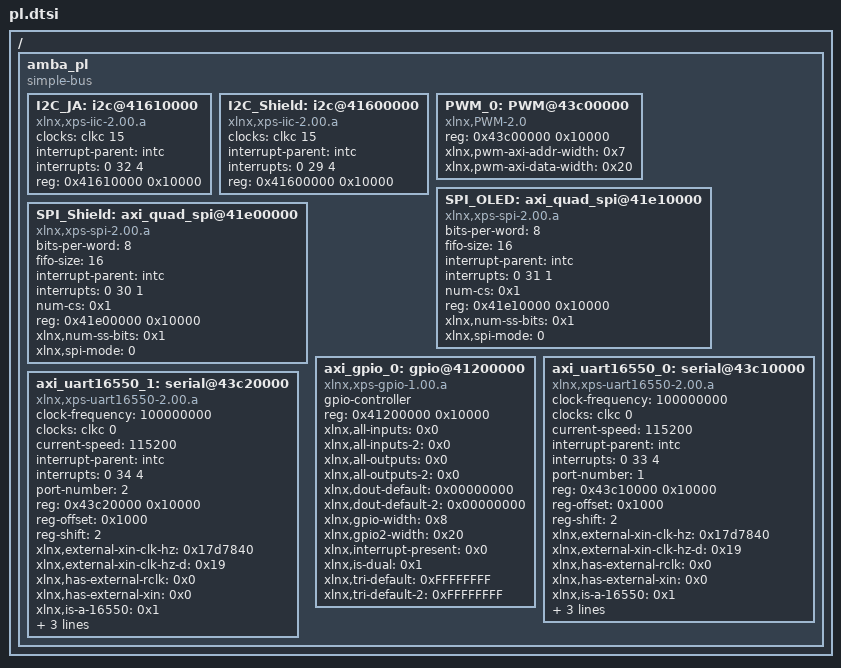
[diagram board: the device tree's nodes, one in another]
/*
 * CAUTION: This file is automatically generated by Xilinx.
 * Version:  
 * Today is: Thu Aug 31 12:42:08 2017
*/


/ {
	amba_pl: amba_pl {
		#address-cells = <1>;
		#size-cells = <1>;
		compatible = "simple-bus";
		ranges ;
		I2C_JA: i2c@41610000 {
			#address-cells = <1>;
			#size-cells = <0>;
			clock-names = "ref_clk";
			clocks = <&clkc 15>;
			compatible = "xlnx,xps-iic-2.00.a";
			interrupt-parent = <&intc>;
			interrupts = <0 32 4>;
			reg = <0x41610000 0x10000>;
		};
		I2C_Shield: i2c@41600000 {
			#address-cells = <1>;
			#size-cells = <0>;
			clock-names = "ref_clk";
			clocks = <&clkc 15>;
			compatible = "xlnx,xps-iic-2.00.a";
			interrupt-parent = <&intc>;
			interrupts = <0 29 4>;
			reg = <0x41600000 0x10000>;
		};
		PWM_0: PWM@43c00000 {
			compatible = "xlnx,PWM-2.0";
			reg = <0x43c00000 0x10000>;
			xlnx,pwm-axi-addr-width = <0x7>;
			xlnx,pwm-axi-data-width = <0x20>;
		};
		SPI_OLED: axi_quad_spi@41e10000 {
			bits-per-word = <8>;
			compatible = "xlnx,xps-spi-2.00.a";
			fifo-size = <16>;
			interrupt-parent = <&intc>;
			interrupts = <0 31 1>;
			num-cs = <0x1>;
			reg = <0x41e10000 0x10000>;
			xlnx,num-ss-bits = <0x1>;
			xlnx,spi-mode = <0>;
		};
		SPI_Shield: axi_quad_spi@41e00000 {
			bits-per-word = <8>;
			compatible = "xlnx,xps-spi-2.00.a";
			fifo-size = <16>;
			interrupt-parent = <&intc>;
			interrupts = <0 30 1>;
			num-cs = <0x1>;
			reg = <0x41e00000 0x10000>;
			xlnx,num-ss-bits = <0x1>;
			xlnx,spi-mode = <0>;
		};
		axi_gpio_0: gpio@41200000 {
			#gpio-cells = <2>;
			compatible = "xlnx,xps-gpio-1.00.a";
			gpio-controller ;
			reg = <0x41200000 0x10000>;
			xlnx,all-inputs = <0x0>;
			xlnx,all-inputs-2 = <0x0>;
			xlnx,all-outputs = <0x0>;
			xlnx,all-outputs-2 = <0x0>;
			xlnx,dout-default = <0x00000000>;
			xlnx,dout-default-2 = <0x00000000>;
			xlnx,gpio-width = <0x8>;
			xlnx,gpio2-width = <0x20>;
			xlnx,interrupt-present = <0x0>;
			xlnx,is-dual = <0x1>;
			xlnx,tri-default = <0xFFFFFFFF>;
			xlnx,tri-default-2 = <0xFFFFFFFF>;
		};
		axi_uart16550_0: serial@43c10000 {
			clock-frequency = <100000000>;
			clock-names = "ref_clk";
			clocks = <&clkc 0>;
			compatible = "xlnx,xps-uart16550-2.00.a", "ns16550a";
			current-speed = <115200>;
			device_type = "serial";
			interrupt-parent = <&intc>;
			interrupts = <0 33 4>;
			port-number = <1>;
			reg = <0x43c10000 0x10000>;
			reg-offset = <0x1000>;
			reg-shift = <2>;
			xlnx,external-xin-clk-hz = <0x17d7840>;
			xlnx,external-xin-clk-hz-d = <0x19>;
			xlnx,has-external-rclk = <0x0>;
			xlnx,has-external-xin = <0x0>;
			xlnx,is-a-16550 = <0x1>;
			xlnx,s-axi-aclk-freq-hz-d = "100.0";
			xlnx,use-modem-ports = <0x1>;
			xlnx,use-user-ports = <0x1>;
		};
		axi_uart16550_1: serial@43c20000 {
			clock-frequency = <100000000>;
			clock-names = "ref_clk";
			clocks = <&clkc 0>;
			compatible = "xlnx,xps-uart16550-2.00.a", "ns16550a";
			current-speed = <115200>;
			device_type = "serial";
			interrupt-parent = <&intc>;
			interrupts = <0 34 4>;
			port-number = <2>;
			reg = <0x43c20000 0x10000>;
			reg-offset = <0x1000>;
			reg-shift = <2>;
			xlnx,external-xin-clk-hz = <0x17d7840>;
			xlnx,external-xin-clk-hz-d = <0x19>;
			xlnx,has-external-rclk = <0x0>;
			xlnx,has-external-xin = <0x0>;
			xlnx,is-a-16550 = <0x1>;
			xlnx,s-axi-aclk-freq-hz-d = "100.0";
			xlnx,use-modem-ports = <0x1>;
			xlnx,use-user-ports = <0x1>;
		};
	};
};
